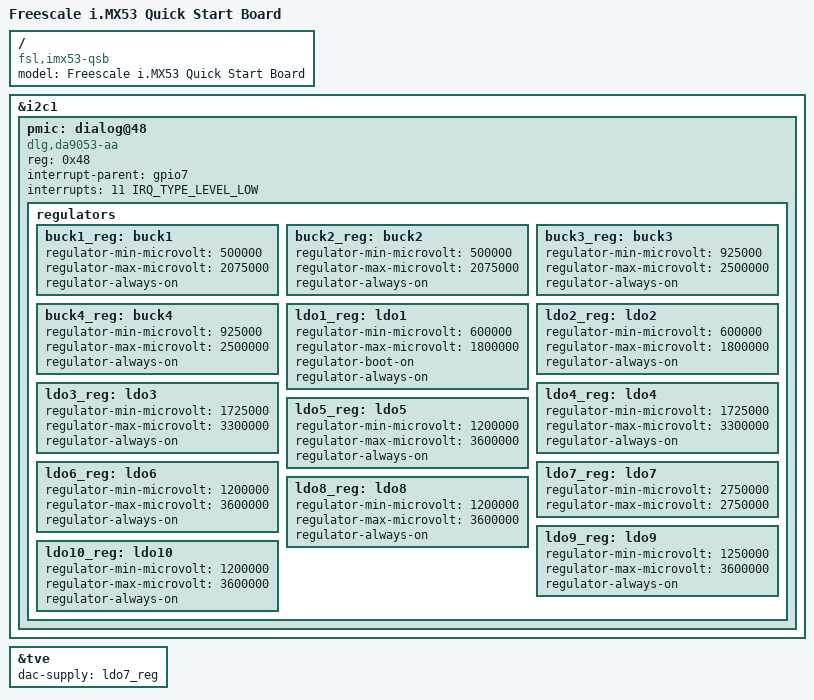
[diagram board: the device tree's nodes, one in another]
// SPDX-License-Identifier: GPL-2.0+
//
// Copyright 2011 Freescale Semiconductor, Inc.
// Copyright 2011 Linaro Ltd.

/dts-v1/;
#include "imx53-qsb-common.dtsi"

/ {
	model = "Freescale i.MX53 Quick Start Board";
	compatible = "fsl,imx53-qsb", "fsl,imx53";
};

&i2c1 {
	pmic: dialog@48 {
		compatible = "dlg,da9053-aa", "dlg,da9052";
		reg = <0x48>;
		interrupt-parent = <&gpio7>;
		interrupts = <11 IRQ_TYPE_LEVEL_LOW>; /* low-level active IRQ at GPIO7_11 */

		regulators {
			buck1_reg: buck1 {
				regulator-min-microvolt = <500000>;
				regulator-max-microvolt = <2075000>;
				regulator-always-on;
			};

			buck2_reg: buck2 {
				regulator-min-microvolt = <500000>;
				regulator-max-microvolt = <2075000>;
				regulator-always-on;
			};

			buck3_reg: buck3 {
				regulator-min-microvolt = <925000>;
				regulator-max-microvolt = <2500000>;
				regulator-always-on;
			};

			buck4_reg: buck4 {
				regulator-min-microvolt = <925000>;
				regulator-max-microvolt = <2500000>;
				regulator-always-on;
			};

			ldo1_reg: ldo1 {
				regulator-min-microvolt = <600000>;
				regulator-max-microvolt = <1800000>;
				regulator-boot-on;
				regulator-always-on;
			};

			ldo2_reg: ldo2 {
				regulator-min-microvolt = <600000>;
				regulator-max-microvolt = <1800000>;
				regulator-always-on;
			};

			ldo3_reg: ldo3 {
				regulator-min-microvolt = <1725000>;
				regulator-max-microvolt = <3300000>;
				regulator-always-on;
			};

			ldo4_reg: ldo4 {
				regulator-min-microvolt = <1725000>;
				regulator-max-microvolt = <3300000>;
				regulator-always-on;
			};

			ldo5_reg: ldo5 {
				regulator-min-microvolt = <1200000>;
				regulator-max-microvolt = <3600000>;
				regulator-always-on;
			};

			ldo6_reg: ldo6 {
				regulator-min-microvolt = <1200000>;
				regulator-max-microvolt = <3600000>;
				regulator-always-on;
			};

			ldo7_reg: ldo7 {
				regulator-min-microvolt = <2750000>;
				regulator-max-microvolt = <2750000>;
			};

			ldo8_reg: ldo8 {
				regulator-min-microvolt = <1200000>;
				regulator-max-microvolt = <3600000>;
				regulator-always-on;
			};

			ldo9_reg: ldo9 {
				regulator-min-microvolt = <1250000>;
				regulator-max-microvolt = <3600000>;
				regulator-always-on;
			};

			ldo10_reg: ldo10 {
				regulator-min-microvolt = <1200000>;
				regulator-max-microvolt = <3600000>;
				regulator-always-on;
			};
		};
	};
};

&tve {
	dac-supply = <&ldo7_reg>;
};
